# CY8C4245AXI_483 register map
File version: 0.1
PSoC 4200
Registers are 8-bit, read-write, no defined reset value unless marked. A register's access mark holds for its fields unless they carry their own. Offsets are from the block's base; lines under a group give offsets from that group; [hi:lo] are bit positions; {n}, {i} and the like mark numbered series; 'fields as' and 'values as' point back to an identical list; <NAME> marks a mode.

## Memory map
0x00000000 timer
0x00000000 xbee — UART

## timer
Base 0x00000000
0x40050108 COUNTER 32-bit — Current counter value
0x4005010C CC 32-bit — Compare / capture value
0x40050110 CC_BUF 32-bit — Compare / capture buffer value
0x40050114 PERIOD 32-bit — Period value
0x40050118 PERIOD_BUF 32-bit — Period buffer value

## xbee — UART
Base 0x00000000
0x400F0020 RX_xbee_RX_ADDRESS1 — RX Address1 Register
0x400F0030 RX_xbee_RX_ADDRESS2 — RX Address2 Register
0x400F0040 RX_xbee_RX_DATA — RX Data Register
0x400F0043 TX_xbee_TX_DATA — TX Data Register
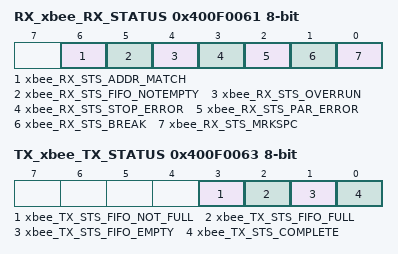
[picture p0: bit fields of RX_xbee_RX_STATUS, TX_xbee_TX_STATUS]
0x400F0061 RX_xbee_RX_STATUS — RX status register
  [6] xbee_RX_STS_ADDR_MATCH ro, [5] xbee_RX_STS_FIFO_NOTEMPTY ro, [4] xbee_RX_STS_OVERRUN ro, [3] xbee_RX_STS_STOP_ERROR ro, [2] xbee_RX_STS_PAR_ERROR ro, [1] xbee_RX_STS_BREAK ro, [0] xbee_RX_STS_MRKSPC ro
0x400F0063 TX_xbee_TX_STATUS — TX status register
  [3] xbee_TX_STS_FIFO_NOT_FULL ro, [2] xbee_TX_STS_FIFO_FULL ro, [1] xbee_TX_STS_FIFO_EMPTY ro, [0] xbee_TX_STS_COMPLETE ro
